# PIC32MZ2025DAH169 device description
Architecture: MIPS; Family: PIC32MZDA; Series: PIC32MZ
Registers are 32-bit, read-write, no defined reset value unless marked. A register's access mark holds for its fields unless they carry their own. Offsets are from the block's base; [hi:lo] are bit positions; {n}, {i} and the like mark numbered series; 'fields as' and 'values as' point back to an identical list.

## DDR_PHY
Instances: DDR_PHY 0x1f8e9100 in periph_indep
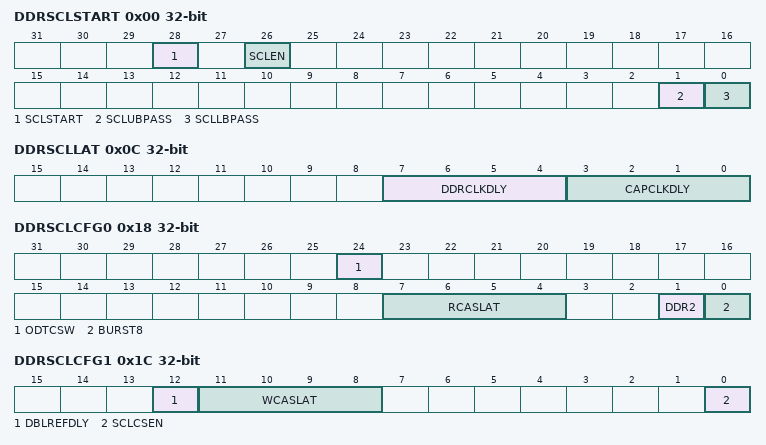
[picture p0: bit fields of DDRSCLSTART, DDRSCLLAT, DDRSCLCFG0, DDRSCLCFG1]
0x00 DDRSCLSTART — DDL SELF CALIBRATION LOGIC START REGISTER
  [28] SCLSTART — Start Self Calibration Logic bit
    1=Start self calibration; 0=Do not start self calibration
  [26] SCLEN — Self Calibration Logic Enable bit
    1=Enable dynamic self calibration logic; 0=Disable dynamic self calibration logic
  [1] SCLUBPASS — Self Calibration Logic Upper Data Byte Status bit
    1=Self calibration logic for upper data byte passed; 0=Self calibration logic for upper data byte failed
  [0] SCLLBPASS — Self Calibration Logic Lower Data Byte Status bit
    1=Self calibration logic for lower data byte passed; 0=Self calibration logic for lower data byte failed
0x0C DDRSCLLAT — DDL Self Calibration Logic Latency Register
  [7:4] DDRCLKDLY, [3:0] CAPCLKDLY
0x18 DDRSCLCFG0 — DDR SCL Configuration Register 0
  [24] ODTCSW — On-Die Termination Chip Select Write bit
    1=ODT is turned on to the DRAM on CS0 during writes performed by the SCL; 0=ODT is turned off to the DRAM on CS0 during writes performed by the SCL
  [7:4] RCASLAT
  [1] DDR2 — DDR2 bit
    1=DDR2 is connected; 0=DDR2 is not connected
  [0] BURST8 — PHY Burst 8 bit
    1=DRAM is in burst 8 mode while running SCL test; 0=DRAM is in burst 4 mode while running SCL test
0x1C DDRSCLCFG1 — DDR SCL Configuration Register 1
  [12] DBLREFDLY — Double Reference Delay bit
    1=SCL operation delay doubled; 0=SCL operation delay not doubled
  [11:8] WCASLAT
  [0] SCLCSEN — SCL Chip Select Enable bit
    1=Run SCL on Chip Select 0; 0=Do not run SCL on Chip Select 0
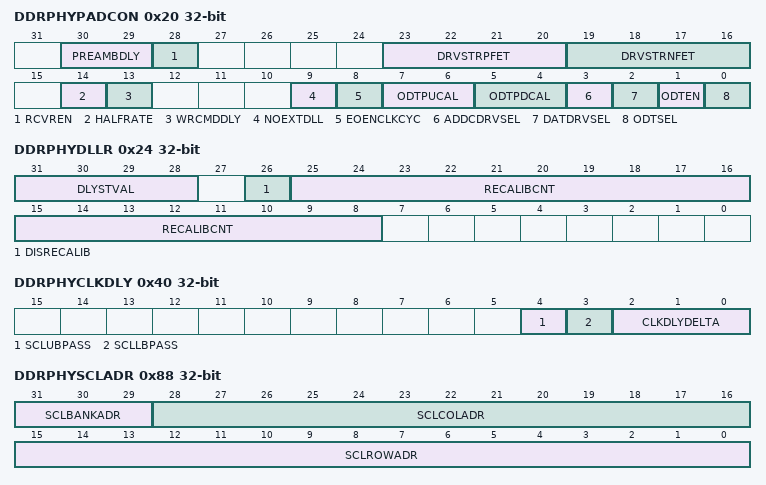
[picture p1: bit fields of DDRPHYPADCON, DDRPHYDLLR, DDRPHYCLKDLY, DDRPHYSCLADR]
0x20 DDRPHYPADCON — DDR PHY Pad Control Register
  [30:29] PREAMBDLY — Preamble Delay bits
    2=1 cycle preamble; 1=1.5 cycle preamble; 0=2 cycle preamble
  [28] RCVREN — Receiver Enable bit
    1=Pad receivers on bidirectional I/Os are turned on; 0=Pad receivers on bidirectional I/Os are turned off
  [23:20] DRVSTRPFET — PFET Drive Strength bits
    15=Maximum drive strength; 0=Minimum drive strength
  [19:16] DRVSTRNFET — NFET Drive Strength bits
    15=Maximum drive strength; 0=Minimum drive strength
  [14] HALFRATE — Half Rate bit
    1=Controller clock is running at half rate with respect to PHY; 0=Controller clock is running at full rate with respect to PHY
  [13] WRCMDDLY — Write Command Delay bit
    1=Write command delay; 0=No Write command delay
  [9] NOEXTDLL — No External DLL bit
    1=Use internal digital DLL; 0=Use external DLL
  [8] EOENCLKCYC — Extra Output Enable bit
    1=Drive pad output enables for an extra clock cycle after a write burst; 0=Do not drive pad output enables for an extra clock cycle after a write burst
  [7:6] ODTPUCAL — On-Die Termination Pull-up Calibration bits
    3=Maximum ODT impedance; 0=Minimum ODT impedance
  [5:4] ODTPDCAL
  [3] ADDCDRVSEL — Address and Control Pads Drive Strength Select bit
    1=Full drive strength; 0=60% Drive Strength
  [2] DATDRVSEL — Data Pad Drive Strength Select bit
    1=Full Drive Strength; 0=60% Drive Strength
  [1] ODTEN — On-Die Termination Enable bit
    1=ODT Enabled; 0=ODT Disabled
  [0] ODTSEL — On-Die Termination Select bit
    1=150 ohm On-Die Termination; 0=75 ohm On-Die Termination
0x24 DDRPHYDLLR — DDR PHY DLL Recalibrate Register
  [31:28] DLYSTVAL
  [26] DISRECALIB — Disable Recalibration bit
    1=Do not recalibrate the digital DLL after the first time; 0=Recalibrate the digital DLL in accordance with the value of the RECALIBCNT bits
  [25:8] RECALIBCNT
0x28 DDRPHYDLLCTRL — DDR Phy Trim Register
  [7:0] DDRDLLTRIM — Trim Setting bits
    ?=These bits control the Trim settings for adjusting the output time of the bank address and control signals with respect to data signals (DQ/DQS). The recommended value is 0x1.
0x40 DDRPHYCLKDLY — DDR Clock Delta Delay Register
  [4] SCLUBPASS — Self Calibration Logic Upper Data Byte Status bit
    2=Self calibration logic for upper data byte is passed; 0=Self calibration logic for upper data byte is failed
  [3] SCLLBPASS — Self Calibration Logic Lower Data Byte Status bit
    2=Self calibration logic for lower data byte is passed; 0=Self calibration logic for lower data byte is failed
  [2:0] CLKDLYDELTA — DDR Clock Delay Delta bits
    {v}={v} DDR clocks (v=0..7)
0x5C DDRADLLBYP — DDR Analog DLL Bypass Register
  [24] ANLDLLBYP — Bypass Analog DLL bit
    1=Bypass the Analog DLL and use the PHY Digital DLL; 0=Reserved; do not use
0x6C DDRSCLCFG2 — DDR Analog DLL Bypass Register
  [1:0] SCLLANSEL — DDR SCL Configuration Register 2
    3=Reserved; do not use; 2=Use the upper byte lane; 1=Use the lower byte lane; 0=Use both lanes
0x88 DDRPHYSCLADR — DDR PHY SCL Address Register
  [31:29] SCLBANKADR — SCL Bank Address bits
    ?=These bits define the bank address to use when running SCL
  [28:16] SCLCOLADR — SCL Column Address bits
    ?=These bits define the column address to use when running SCL
  [15:0] SCLROWADR — SCL Row Address bits
    values as SCLCOLADR

## Notices in the file
Copyright (c) 2017 Microchip Technology Inc.
SPDX-License-Identifier: Apache-2.0
Licensed under the Apache License, Version 2.0 (the "License");
you may not use this file except in compliance with the License.
You may obtain a copy of the License at
http://www.apache.org/licenses/LICENSE-2.0
Unless required by applicable law or agreed to in writing, software
distributed under the License is distributed on an "AS IS" BASIS,
WITHOUT WARRANTIES OR CONDITIONS OF ANY KIND, either express or implied.
See the License for the specific language governing permissions and
limitations under the License.
